# ATtiny9 device description
Architecture: AVR8L; Family: tinyAVR
Programming and debug interfaces: TPI
Registers are 8-bit, access not given, no defined reset value unless marked. A register's access mark holds for its fields unless they carry their own. Offsets are from the block's base; lines under a group give offsets from that group; [hi:lo] are bit positions; {n}, {i} and the like mark numbered series; 'fields as' and 'values as' point back to an identical list; <NAME> marks a mode.

## Ordering variants
ATtiny9-TSHR: SOT23-6, pinout SOT23_6, up to 12 MHz, -40 to 85 C, 1.8 to 5.5 V
ATtiny9-MAHR: UDFN8, up to 12 MHz, -40 to 85 C, 1.8 to 5.5 V
ATtiny9-TS8R: SOT23-6, pinout SOT23_6, up to 10 MHz, -40 to 125 C, 1.8 to 5.5 V

## Memory
prog space: start 0x0000 size 0x0400, little endian
  0x0000 FLASH size 0x0400 flash, rw, executable, page 0x80
signatures space: start 0 size 3, little endian
  0 SIGNATURES size 3 signatures, ro
fuses space: start 0 size 0x0001, little endian
  0 FUSES size 0x0001 fuses, rw
lockbits space: start 0 size 0x0001, little endian
  0 LOCKBITS size 0x0001 lockbits, rw
data space: start 0x0000 size 0x4400, little endian
  0x0000 IO size 0x40 io
  0x0040 SRAM size 0x20 ram
  0x3F00 MAPPED_NVM_LOCK_BITS size 0x0002 sysreg
  0x3F40 MAPPED_CONFIGURATION_BITS size 0x0002 sysreg
  0x3F80 MAPPED_CALIBRATION_BITS size 0x0002 sysreg
  0x3FC0 MAPPED_DEVICE_ID_BITS size 0x0004 sysreg
  0x4000 MAPPED_FLASH size 0x0400 flash

## Peripheral instances (address, pins/pin function, parameters)
AC at 0x00 — Analog Comparator
  pins: AIN0 PB0; AIN1 PB1
CPU at 0x00 — CPU Registers
  parameters: CORE_VERSION=AVR8L_0
PORTB at 0x00 — I/O Port
  pins: P0 PB0; P1 PB1; P2 PB2; P3 PB3
EXINT at 0x00 — External Interrupts
  pins: PCINT0 PB0; PCINT1 PB1; PCINT2 PB2; PCINT3 PB3; INT0 PB2
TC0 at 0x00 — Timer/Counter, 16-bit
  pins: OCA PB0; OCB PB1; T PB2
WDT at 0x00 — Watchdog Timer
FUSE at 0 in fuses — Fuses
LOCKBIT at 0 in lockbits — Lockbits

## Interrupts
0 RESET — External Reset, Power-on Reset and Watchdog Reset
1 INT0 — External Interrupt Request 0
2 PCINT0 — Pin Change Interrupt Request 0
3 TIM0_CAPT — Timer/Counter0 Input Capture
4 TIM0_OVF — Timer/Counter0 Overflow
5 TIM0_COMPA — Timer/Counter Compare Match A
6 TIM0_COMPB — Timer/Counter Compare Match B
7 ANA_COMP — Analog Comparator
8 WDT — Watchdog Time-out
9 VLM — Vcc Voltage Level Monitor

## Properties
SIGNATURES: SIGNATURE0=0x1e, SIGNATURE1=0x90, SIGNATURE2=0x08

## Pinouts (pin number, pad)
SOT23_6: 1 PB0, 2 GND, 3 PB1, 4 PB2, 5 VCC, 6 PB3
UDFN8: 1 PB1, 4 GND, 5 PB0, 6 PB3, 7 VCC, 8 PB2

## FUSE — Fuses
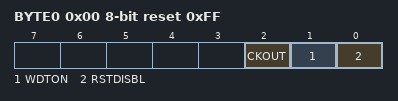
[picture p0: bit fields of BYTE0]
0x00 BYTE0 reset 0xFF
  [2] CKOUT — Output external clock
  [1] WDTON — Watch dog timer always on
  [0] RSTDISBL — Disable external reset

## LOCKBIT — Lockbits
0x00 LOCKBIT reset 0xFF
  [1:0] LB — Memory Lock
    0=PROG_VER_DISABLED (Further programming and verification disabled); 2=PROG_DISABLED (Further programming disabled); 3=NO_LOCK (No memory lock features enabled)

## AC — Analog Comparator
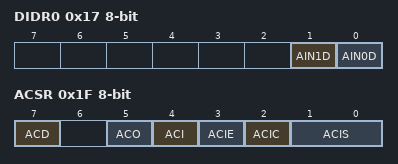
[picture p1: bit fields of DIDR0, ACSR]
0x17 DIDR0
  [1] AIN1D — AIN1 Digital Input Disable
  [0] AIN0D — AIN0 Digital Input Disable
0x1F ACSR — Analog Comparator Control And Status Register
  [7] ACD — Analog Comparator Disable
  [5] ACO — Analog Compare Output
  [4] ACI — Analog Comparator Interrupt Flag
  [3] ACIE — Analog Comparator Interrupt Enable
  [2] ACIC — Analog Comparator Input Capture Enable
  [1:0] ACIS — Analog Comparator Interrupt Mode Select bits
    0=Interrupt on Toggle; 2=Interrupt on Falling Edge; 3=Interrupt on Rising Edge

## CPU — CPU Registers
0x32 NVMCSR — Non-Volatile Memory Control and Status Register
  [7] NVMBSY — Non-Volatile Memory Busy
0x33 NVMCMD bits used 5:0 — Non-Volatile Memory Command
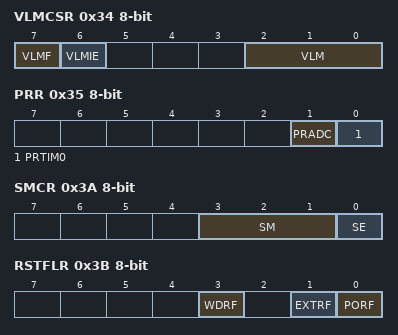
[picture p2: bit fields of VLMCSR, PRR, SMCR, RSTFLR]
0x34 VLMCSR — Vcc Level Monitoring Control and Status Register
  [7] VLMF — VLM Flag
  [6] VLMIE — VLM Interrupt Enable
  [2:0] VLM — Trigger Level of Voltage Level Monitor bits
0x35 PRR — Power Reduction Register
  [1] PRADC — Power Reduction ADC
  [0] PRTIM0 — Power Reduction Timer/Counter0
0x36 CLKPSR — Clock Prescale Register
  [3:0] CLKPS — Clock Prescaler Select Bits
    0=1; 1=2; 2=4; 3=8; 4=16; 5=32; 6=64; 7=128; 8=256
0x37 CLKMSR — Clock Main Settings Register
  [1:0] CLKMS — Clock Main Select Bits
0x39 OSCCAL — Oscillator Calibration Value
0x3A SMCR — Sleep Mode Control Register
  [3:1] SM — Sleep Mode Select Bits
    0=IDLE; 1=ADC (ADC Noise Reduction); 2=PDOWN (Power Down); 4=STDBY (Standby)
  [0] SE — Sleep Enable
0x3B RSTFLR — Reset Flag Register
  [3] WDRF — Watchdog Reset Flag
  [1] EXTRF — External Reset Flag
  [0] PORF — Power-on Reset Flag
0x3C CCP — Configuration Change Protection
0x3D SP 16-bit — Stack Pointer
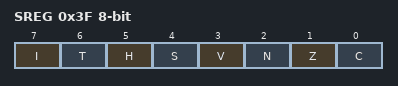
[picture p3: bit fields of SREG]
0x3F SREG — Status Register
  [7] I — Global Interrupt Enable
  [6] T — Bit Copy Storage
  [5] H — Half Carry Flag
  [4] S — Sign Bit
  [3] V — Two's Complement Overflow Flag
  [2] N — Negative Flag
  [1] Z — Zero Flag
  [0] C — Carry Flag

## PORTB — I/O Port
0x00 PINB bits used 3:0 — Port B Data register
0x01 DDRB bits used 3:0 — Data Direction Register, Port B
0x02 PORTB bits used 3:0 — Input Pins, Port B
0x03 PUEB bits used 3:0 — Pull-up Enable Control Register
0x0C PORTCR — Port Control Register
  [1] BBMB — Break-Before-Make Mode Enable

## EXINT — External Interrupts
0x10 PCMSK — Pin Change Mask Register
  [3:0] PCINT — Pin Change Enable Masks
0x11 PCIFR — Pin Change Interrupt Flag Register
  [0] PCIF0 — Pin Change Interrupt Flag 0
0x12 PCICR — Pin Change Interrupt Control Register
  [0] PCIE0 — Pin Change Interrupt Enable 0
0x13 EIMSK — External Interrupt Mask register
  [0] INT0 — External Interrupt Request 0 Enable
0x14 EIFR — External Interrupt Flag register
  [0] INTF0 — External Interrupt Flag 0
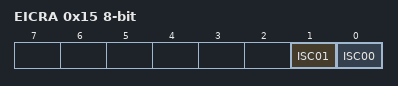
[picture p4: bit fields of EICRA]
0x15 EICRA — External Interrupt Control Register A
  [1] ISC01 — Interrupt Sense Control 0 Bit 1
  [0] ISC00 — Interrupt Sense Control 0 Bit 0

## TC0 (TC16 module) — Timer/Counter, 16-bit
0x22 ICR0 16-bit — Input Capture Register Bytes
0x24 OCR0B 16-bit — Timer/Counter0 Output Compare Register B
0x26 OCR0A 16-bit — Timer/Counter 0 Output Compare Register A
0x28 TCNT0 16-bit — Timer/Counter0
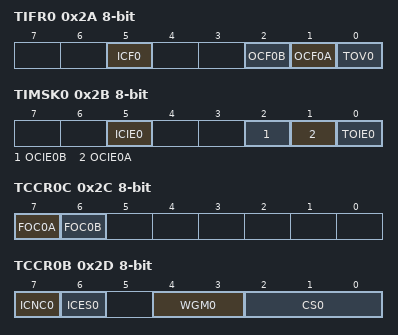
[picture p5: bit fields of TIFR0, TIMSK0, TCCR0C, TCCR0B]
0x2A TIFR0 — Overflow Interrupt Enable
  [5] ICF0 — Input Capture Flag
  [2] OCF0B — Timer Output Compare Flag 0B
  [1] OCF0A — Timer Output Compare Flag 0A
  [0] TOV0 — Timer Overflow Flag
0x2B TIMSK0 — Timer Interrupt Mask Register 0
  [5] ICIE0 — Input Capture Interrupt Enable
  [2] OCIE0B — Output Compare B Match Interrupt Enable
  [1] OCIE0A — Output Compare A Match Interrupt Enable
  [0] TOIE0 — Overflow Interrupt Enable
0x2C TCCR0C — Timer/Counter 0 Control Register C
  [7] FOC0A — Force Output Compare for Channel A
  [6] FOC0B — Force Output Compare for Channel B
0x2D TCCR0B — Timer/Counter 0 Control Register B
  [7] ICNC0 — Input Capture Noise Canceler
  [6] ICES0 — Input Capture Edge Select
  [4:3] WGM0 (bit 2 of the value upward) — Waveform Generation Mode
  [2:0] CS0 — Clock Select
    0=No Clock Source (Stopped); 1=Running, No Prescaling; 2=Running, CLK/8; 3=Running, CLK/64; 4=Running, CLK/256; 5=Running, CLK/1024; 6=Running, ExtClk Tn Falling Edge; 7=Running, ExtClk Tn Rising Edge
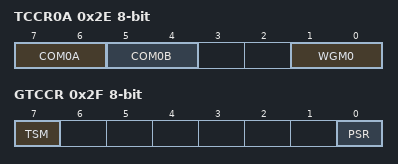
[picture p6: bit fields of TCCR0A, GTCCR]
0x2E TCCR0A — Timer/Counter 0 Control Register A
  [7:6] COM0A — Compare Output Mode for Channel A bits
  [5:4] COM0B — Compare Output Mode for Channel B bits
  [1:0] WGM0 — Waveform Generation Mode
0x2F GTCCR — General Timer/Counter Control Register
  [7] TSM — Timer Synchronization Mode
  [0] PSR — Prescaler Reset

## WDT — Watchdog Timer
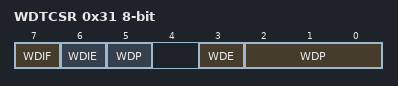
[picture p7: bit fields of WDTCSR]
0x31 WDTCSR — Watchdog Timer Control and Status Register
  [7] WDIF — Watchdog Timer Interrupt Flag
  [6] WDIE — Watchdog Timer Interrupt Enable
  [3] WDE — Watch Dog Enable
  [5,2:0] WDP — Watchdog Timer Prescaler Bits
    0=Oscillator Cycles 2K; 1=Oscillator Cycles 4K; 2=Oscillator Cycles 8K; 3=Oscillator Cycles 16K; 4=Oscillator Cycles 32K; 5=Oscillator Cycles 64K; 6=Oscillator Cycles 128K; 7=Oscillator Cycles 256K; 8=Oscillator Cycles 512K; 9=Oscillator Cycles 1024K
